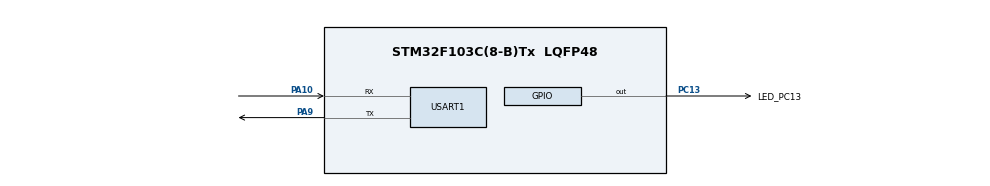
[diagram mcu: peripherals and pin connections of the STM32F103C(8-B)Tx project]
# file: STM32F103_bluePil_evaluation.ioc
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Mcu.Family=STM32F1
Mcu.Name=STM32F103C(8-B)Tx
Mcu.Package=LQFP48
NVIC.PriorityGroup=NVIC_PRIORITYGROUP_4
NVIC.USART1_IRQn=true\:0\:0\:false\:false\:true\:true\:true
PA10.Mode=Asynchronous
PA10.Signal=USART1_RX
PA13.Mode=Serial_Wire
PA13.Signal=SYS_JTMS-SWDIO
PA14.Mode=Serial_Wire
PA14.Signal=SYS_JTCK-SWCLK
PA9.Mode=Asynchronous
PA9.Signal=USART1_TX
PC13-TAMPER-RTC.GPIO_Label=LED_PC13
PC13-TAMPER-RTC.GPIO_ModeDefaultOutputPP=GPIO_MODE_OUTPUT_OD
PC13-TAMPER-RTC.Signal=GPIO_Output
ProjectManager.HeapSize=0x200
ProjectManager.StackSize=0x400
ProjectManager.TargetToolchain=TrueSTUDIO
RCC.APB1Freq_Value=8000000
RCC.APB2Freq_Value=8000000
USART1.VirtualMode=VM_ASYNC
board=custom

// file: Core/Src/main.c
/* USER CODE BEGIN Header */
/**
  ******************************************************************************
  * @file           : main.c
  * @brief          : Main program body
  ******************************************************************************
  * @attention
  *
  * <h2><center>&copy; Copyright (c) 2020 STMicroelectronics.
  * All rights reserved.</center></h2>
  *
  * This software component is licensed by ST under BSD 3-Clause license,
  * the "License"; You may not use this file except in compliance with the
  * License. You may obtain a copy of the License at:
  *                        opensource.org/licenses/BSD-3-Clause
  *
  ******************************************************************************
  */
/* USER CODE END Header */

#include "main.h"
#include "usart.h"
#include "gpio.h"

/* USER CODE BEGIN Includes */
#include "ring_buffer.h"

#include <string.h>
#include "num_str_convert.h"

//#include "Serial.h"
#include "Serial_test.h"

/* USER CODE END Includes */

void SystemClock_Config(void);

int main(void)
{

  /* MCU Configuration--------------------------------------------------------*/

  /* Reset of all peripherals, Initializes the Flash interface and the Systick. */
  HAL_Init();

  /* USER CODE BEGIN Init */
    // RingBuff_init(&ringBuffer_test, buffer_data, sizeof(buffer_data));
    // RingBuff.push(&ringBuffer_test, 'a');
    // RingBuff.push(&ringBuffer_test, 'b');
    // RingBuff.push(&ringBuffer_test, 'c');

    // x = RingBuff.get_nBytes(&ringBuffer_test);

  /* USER CODE END Init */

  /* Configure the system clock */
  SystemClock_Config();

  /* Initialize all configured peripherals */
  MX_GPIO_Init();
  MX_USART1_UART_Init();
  /* USER CODE BEGIN 2 */

    serial_test_init();

  /* USER CODE END 2 */

  /* Infinite loop */
  while (1)
  {

    serial_test_exe();

  }
}

void SystemClock_Config(void)
{
  RCC_OscInitTypeDef RCC_OscInitStruct = {0};
  RCC_ClkInitTypeDef RCC_ClkInitStruct = {0};

  /** Initializes the CPU, AHB and APB busses clocks
  */
  RCC_OscInitStruct.OscillatorType = RCC_OSCILLATORTYPE_HSI;
  RCC_OscInitStruct.HSIState = RCC_HSI_ON;
  RCC_OscInitStruct.HSICalibrationValue = RCC_HSICALIBRATION_DEFAULT;
  RCC_OscInitStruct.PLL.PLLState = RCC_PLL_NONE;
  if (HAL_RCC_OscConfig(&RCC_OscInitStruct) != HAL_OK)
  {
    Error_Handler();
  }
  /** Initializes the CPU, AHB and APB busses clocks
  */
  RCC_ClkInitStruct.ClockType = RCC_CLOCKTYPE_HCLK|RCC_CLOCKTYPE_SYSCLK
                              |RCC_CLOCKTYPE_PCLK1|RCC_CLOCKTYPE_PCLK2;
  RCC_ClkInitStruct.SYSCLKSource = RCC_SYSCLKSOURCE_HSI;
  RCC_ClkInitStruct.AHBCLKDivider = RCC_SYSCLK_DIV1;
  RCC_ClkInitStruct.APB1CLKDivider = RCC_HCLK_DIV1;
  RCC_ClkInitStruct.APB2CLKDivider = RCC_HCLK_DIV1;

  if (HAL_RCC_ClockConfig(&RCC_ClkInitStruct, FLASH_LATENCY_0) != HAL_OK)
  {
    Error_Handler();
  }
}

void Error_Handler(void)
{
}

/************************ (C) COPYRIGHT STMicroelectronics *****END OF FILE****/
